# YTM32B1MD2 register map
Vendor: YTMicro; File version: 1.0
CPU: CM33 r0p4, little endian, MPU, FPU, 2 interrupt priority bits
Registers are 32-bit, read-write, reset 0x0 unless marked. A register's access mark holds for its fields unless they carry their own. Offsets are from the block's base; [hi:lo] are bit positions; {n}, {i} and the like mark numbered series; <NAME> marks a mode.

## pTMR0 — Periodic timer
Base 0x4005A000; register names take the prefix pTMR0_
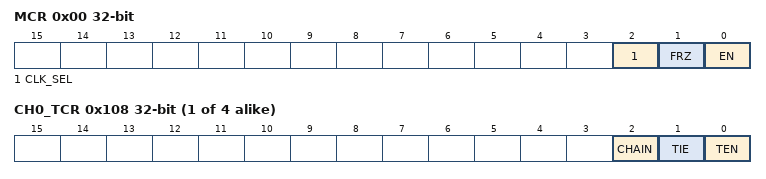
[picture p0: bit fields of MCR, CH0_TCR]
0x00 MCR
  [2] CLK_SEL — Select the timer clock source from bus clock or func clock.
    0=pTMR timer clock select bus clock; 1=pTMR timer clock select func clock, if select func clock as ptmr timer clock, need to be met 2*func clock frequence < bus clock frequence
  [1] FRZ — Allows the timers to be stopped when the device enters debug mode.
    0=pTMR continues to run in debug mode; 1=pTMR stops in debug mode
  [0] EN — Enable pTMR module.
    0=pTMR is disabled; 1=pTMR is enabled
{0x100+0x10*i} CH{i}_TSV (i=0..3) — Timer Start Value Register.
  [31:0] STVAL — This register set the timer start value. The timer will count down until it reaches 0, then it will generate an interrupt and loads the value again. Writing a new value to this register will not restart the timer, instead the value will be loaded once the timer expires. To abort the current cycle and start a timer period with the new value, the timer must be disabled and enabled again.
{0x104+0x10*i} CH{i}_TCV (i=0..3) — Timer Current Value Register
  [31:0] CVAL — This register stands for current timer value when user read this register. The value of this register will be frozen in debug mode if MCR[FRZ] is set.
{0x108+0x10*i} CH{i}_TCR (i=0..3) — Timer Control Register
  [2] CHAIN — When setting this bit, it will link multi-channel in sequence to combine a new bits counter, it just links the front channel.
    0=Chaining is disabled, channel timer runs independently; 1=Chaining is enabled
  [1] TIE — Enable interrupt when setting this bit.
    0=Disable timer interrupt of corresponding channel; 1=Enable timer interrupt of corresponding channel
  [0] TEN — Enable the timer of corresponding channel.
    0=Disable the timer of corresponding channel; 1=Enable the timer of corresponding channel
{0x10C+0x10*i} CH{i}_TFR (i=0..3) — Timer Flag Register
  [0] TIF — Hardware will set this bit as 1 when timer timeout occur, and writing logic 1 to this bit will clear this bit as 0.
    0=Timeout did not occur; 1=Timeout occurred

## lpTMR0 — Low Power Timer
Base 0x4005D000; register names take the prefix lpTMR0_
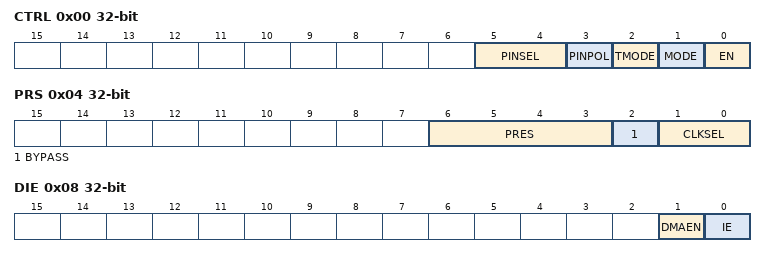
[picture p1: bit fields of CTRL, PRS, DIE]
0x00 CTRL
  [5:4] PINSEL — Configures the input source to be used in Pulse Counter mode. PINSEL must be altered only when the lpTMR is disabled.
    0=Pulse counter input 0 is selected. (It's from TMU); 1=Pulse counter input 1 is selected. (It's from lpTMR_ALT1 pad); 2=Pulse counter input 2 is selected. (It's from lpTMR_ALT2 pad); 3=Pulse counter input 3 is selected. (It's from lpTMR_ALT3 pad)
  [3] PINPOL — Configures the polarity of the input source in Pulse Counter mode. PINPOL must be changed only when the lpTMR is disabled.
    0=Pulse Counter input source is active-high, and the CNT will increment on the rising-edge; 1=Pulse Counter input source is active-low, and the CNT will increment on the falling-edge
  [2] TMODE — When clear, TMODE configures the CNT to reset whenever CCF is set. When set, TMODE configures the CNT to reset on overflow. TMODE must be altered only when the lpTMR is disabled.
    0=CNT is reset whenever CCF is set; 1=CNT is reset on overflow
  [1] MODE — Configures the mode of the lpTMR. MODE must be altered only when the lpTMR is disabled.
    0=Time Counter mode; 1=Pulse Counter mode
  [0] EN — When EN is clear, it resets the lpTMR internal logic, including the CNT and CCF. When EN is set, the lpTMR is enabled. While writing 1 to this field, CTRL[5:1] must not be altered.
    0=lpTMR is disabled and internal logic is reset; 1=lpTMR is enabled
0x04 PRS
  [6:3] PRES — Configures the size of the Prescaler in Time Counter mode or width of the glitch filter in Pulse Counter mode. The width of the glitch filter can vary by 1 cycle due to synchronization of the pulse counter input. ewline Prescaler divides the prescaler clock by 2^(PRES+1) and glitch filter recognizes change on input pin after 2^PRES rising clock edges. ewline PRESCALE must be altered only when the lpTMR is disabled.
  [2] BYPASS — When BYPASS is set, the selected prescaler clock in Time Counter mode or selected input source in Pulse Counter mode directly clocks the CNT. When BYPASS is clear, the CNT is clocked by the output of the prescaler/glitch filter. BYPASS must be altered only when the lpTMR is disabled.
  [1:0] CLKSEL — Use to select function clock source.
    0=FIRC Clock; 1=SIRC Clock; 2=FXOSC Clock; 3=LPO_CLK
0x08 DIE
  [1] DMAEN — When DMAEN is set, the lpTMR DMA Request is generated whenever CCF is also set and the CCF is cleared when the DMA Controller is done.
    0=Timer DMA Request disabled; 1=Timer DMA Request enabled
  [0] IE — When IE is set, the lpTMR Interrupt is generated whenever CCF is also set.
    0=Timer interrupt disabled; 1=Timer interrupt enabled
0x0C STS
  [0] CCF — CCF is set when the lpTMR is enabled and the CNT equals the CMP and increments. CCF is cleared when the lpTMR is disabled or writing 1 to it.
    0=The value of CNT is not equal to CMP and increments; 1=The value of CNT is equal to CMP and increments
0x10 CMP
  [15:0] CMP — When the lpTMR is enabled and the CNT equals the value in the CMP and increments, CCF is set and the hardware trigger asserts until the next time the CNT increments. If the CMP is 0, the hardware trigger will remain asserted until the lpTMR is disabled. If the lpTMR is enabled, the CMP must be altered only when CCF is set.
0x14 LCNT wo
  [15:0] LCVAL — Write this register to latch timer counter value to CNT register, which is to avoid metastability.
0x18 CNT
  [15:0] CVAL — The CNT returns the current value of the lpTMR counter at the time this LCNT register was last written.
